# Template register map
Vendor: VendorName Co.Ltd; Series: SeriesName; File version: 1.2
CPU: CM7 r0p1, little endian, MPU, FPU, 4 interrupt priority bits
Registers are 32-bit, read-write, no defined reset value unless marked. A register's access mark holds for its fields unless they carry their own. Offsets are from the block's base; [hi:lo] are bit positions; lines under a group give offsets from that group; {n}, {i} and the like mark numbered series; 'fields as' and 'values as' point back to an identical list.

## XBAR — Crossbar
Base 0x40036000
{0x0+0x10*i} EPWMAOUTXMUX[{i}] (i=0..7) group — Grouping of EPWMAOUTx signal from MUX0 to MUX63
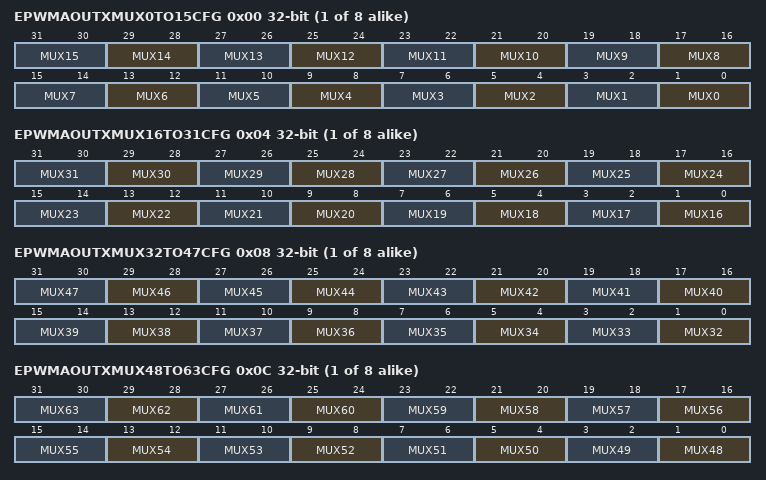
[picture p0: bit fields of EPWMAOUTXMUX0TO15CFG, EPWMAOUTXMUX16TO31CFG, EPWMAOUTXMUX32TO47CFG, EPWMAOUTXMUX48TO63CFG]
  0x00 EPWMAOUTXMUX0TO15CFG — EPWM XBAR A OUTx multiplexing config register 1
    [2n+1:2n] MUX{n} (n=0..15) — XBAR MUX{n}[1:0] bit: input signal of EPWM XBAR A OUTxMUX{n} select
  0x04 EPWMAOUTXMUX16TO31CFG — EPWM XBAR A OUTx multiplexing config register 2
    [2n-31:2n-32] MUX{n} (n=16..31) — XBAR MUX{n}[1:0] bit: input signal of EPWM XBAR A OUTxMUX{n} select
  0x08 EPWMAOUTXMUX32TO47CFG — EPWM XBAR A OUTx multiplexing config register 3
    [2n-63:2n-64] MUX{n} (n=32..47) — XBAR MUX{n}[1:0] bit: input signal of EPWM XBAR A OUTxMUX{n} select
  0x0C EPWMAOUTXMUX48TO63CFG — EPWM XBAR A OUTx multiplexing config register 4
    [2n-95:2n-96] MUX{n} (n=48..63) — XBAR MUX{n}[1:0] bit: input signal of EPWM XBAR A OUTxMUX{n} select
{0x80+8i} EPWMAOUTPUTXMUXEN[{i}] (i=0..7) group — Grouping of EPWMAOUTx enable from MUX0 to MUX63
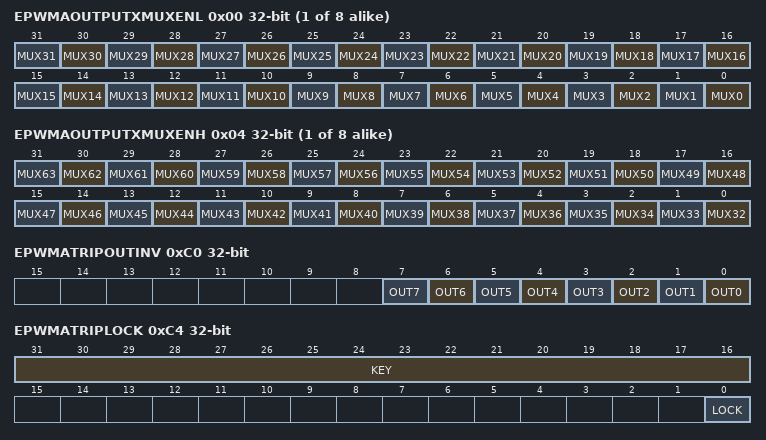
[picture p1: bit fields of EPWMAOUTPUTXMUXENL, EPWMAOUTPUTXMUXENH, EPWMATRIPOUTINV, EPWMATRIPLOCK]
  0x00 EPWMAOUTPUTXMUXENL — EPWM XBAR A OUTx enable register 1
    [n] MUX{n} (n=0..31) — XBAR MUX{n} bit: select output of MUX{n} to drive OUTPUTx of EPWM XBAR A
  0x04 EPWMAOUTPUTXMUXENH — EPWM XBAR A OUTx enable register 2
    [n-32] MUX{n} (n=32..63) — XBAR MUX{n} bit: select output of MUX{n} to drive OUTPUTx of EPWM XBAR A
0xC0 EPWMATRIPOUTINV — EPWM XBAR A output inverse register
  [n] OUT{n} (n=0..7) — XBAR OUT{n} bit: select polarity of EPWM XBAR A's TRIP{n+5}
0xC4 EPWMATRIPLOCK — EPWM XBAR A config lock register
  [31:16] KEY wo — XBAR KEY[15:0] bit: only when 0x5A5A is written can this register be written
  [0] LOCK — XBAR LOCK bit: writing lock of EPWM XBAR A register
{0x100+0x10*i} EPWMBOUTXMUX[{i}] (i=0..7) group — Grouping of EPWMBOUTx signal from MUX0 to MUX63
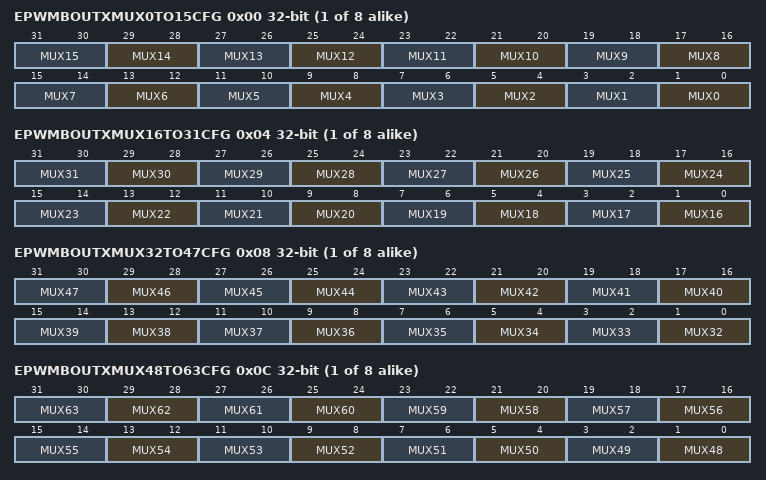
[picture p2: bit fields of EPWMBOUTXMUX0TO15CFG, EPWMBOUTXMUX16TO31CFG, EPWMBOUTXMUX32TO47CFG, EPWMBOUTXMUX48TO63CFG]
  0x00 EPWMBOUTXMUX0TO15CFG — EPWM XBAR B OUTx multiplexing config register 1
    [2n+1:2n] MUX{n} (n=0..15) — XBAR MUX{n}[1:0] bit: input signal of EPWM XBAR B OUTxMUX{n} select
  0x04 EPWMBOUTXMUX16TO31CFG — EPWM XBAR B OUTx multiplexing config register 2
    [2n-31:2n-32] MUX{n} (n=16..31) — XBAR MUX{n}[1:0] bit: input signal of EPWM XBAR B OUTxMUX{n} select
  0x08 EPWMBOUTXMUX32TO47CFG — EPWM XBAR B OUTx multiplexing config register 3
    [2n-63:2n-64] MUX{n} (n=32..47) — XBAR MUX{n}[1:0] bit: input signal of EPWM XBAR B OUTxMUX{n} select
  0x0C EPWMBOUTXMUX48TO63CFG — EPWM XBAR B OUTx multiplexing config register 4
    [2n-95:2n-96] MUX{n} (n=48..63) — XBAR MUX{n}[1:0] bit: input signal of EPWM XBAR B OUTxMUX{n} select
{0x180+8i} EPWMBOUTPUTXMUXEN[{i}] (i=0..7) group — Grouping of EPWMBOUTx enable from MUX0 to MUX63
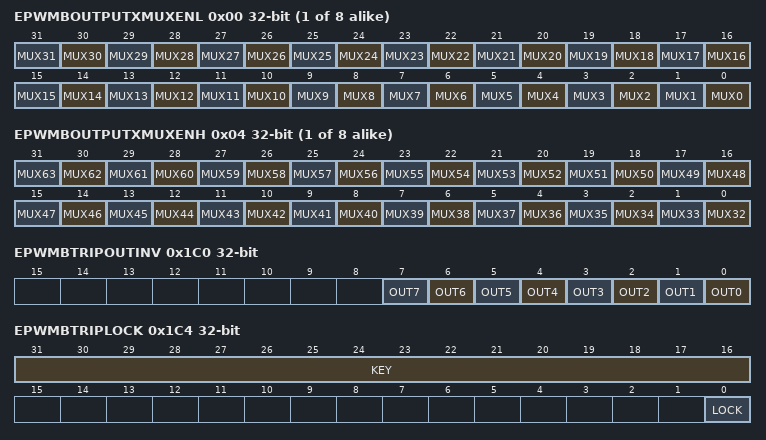
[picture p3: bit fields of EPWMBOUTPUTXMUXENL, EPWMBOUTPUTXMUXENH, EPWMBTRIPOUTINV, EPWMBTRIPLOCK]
  0x00 EPWMBOUTPUTXMUXENL — EPWM XBAR B OUTx enable register 1
    [n] MUX{n} (n=0..31) — XBAR MUX{n} bit: select output of MUX{n} to drive OUTPUTx of EPWM XBAR B
  0x04 EPWMBOUTPUTXMUXENH — EPWM XBAR B OUTx enable register 2
    [n-32] MUX{n} (n=32..63) — XBAR MUX{n} bit: select output of MUX{n} to drive OUTPUTx of EPWM XBAR B
0x1C0 EPWMBTRIPOUTINV — EPWM XBAR B output inverse register
  [n] OUT{n} (n=0..7) — XBAR OUT{n} bit: select polarity of EPWM XBAR B's TRIP{n+5}
0x1C4 EPWMBTRIPLOCK — EPWM XBAR B config lock register
  [31:16] KEY wo — XBAR KEY[15:0] bit: only when 0x5A5A is written can this register be written
  [0] LOCK — XBAR LOCK bit: writing lock of EPWM XBAR B register
{0x200+4i} INPUTXSEL[{i}] (i=0..15) — Grouping of INPUTxSEL
  [15:0] SELECT — XBAR SELECT[15:0] bit: select GPIO for INPUTx signal
0x240 INPUTSELLOCK — XBAR input selection lock register
  [15:0] INPUTSELLOCK — XBAR INPUTSELLOCK[15:0] bit: lock bit for INPUTxSELECT register
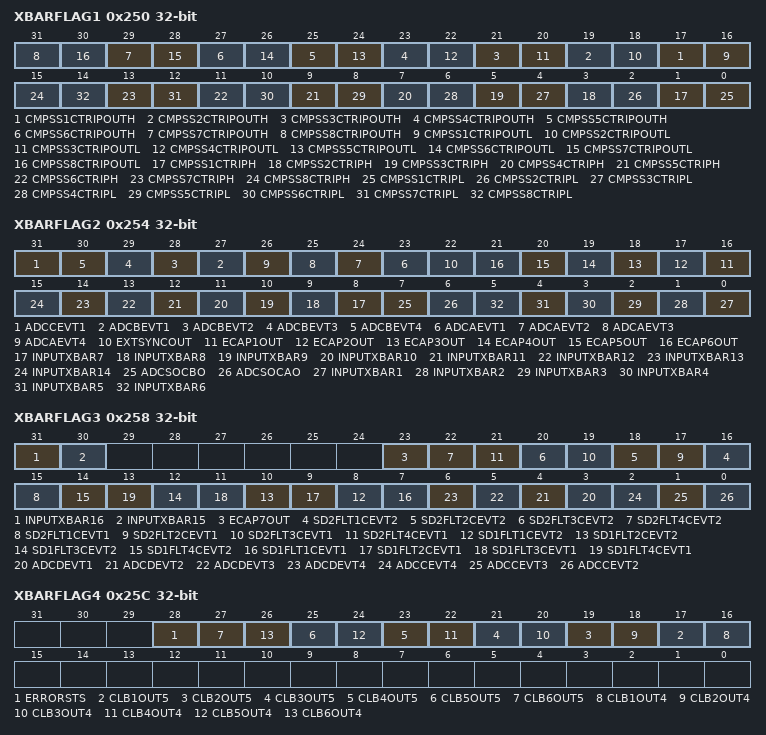
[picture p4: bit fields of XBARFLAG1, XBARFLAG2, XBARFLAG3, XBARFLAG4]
0x250 XBARFLAG1 ro — XBAR input flag register 1
  [2n+15] CMPSS{n}CTRIPOUTH (n=1..8) — XBAR CMPSS{n}CTRIPOUTH bit: whether CMPSS{n}CTRIPOUTH input was triggered
  [2n+14] CMPSS{n}CTRIPOUTL (n=1..8) — XBAR CMPSS{n}CTRIPOUTL bit: whether CMPSS{n}CTRIPOUTL input was triggered
  [2n-1] CMPSS{n}CTRIPH (n=1..8) — XBAR CMPSS{n}CTRIPH bit: whether CMPSS{n}CTRIPH input was triggered
  [2n-2] CMPSS{n}CTRIPL (n=1..8) — XBAR CMPSS{n}CTRIPL bit: whether CMPSS{n}CTRIPL input was triggered
0x254 XBARFLAG2 ro — XBAR flag register 2
  [31] ADCCEVT1 — XBAR ADCCEVT1 bit: whether ADCCEVT1 input was triggered
  [n+26] ADCBEVT{n} (n=1..4) — XBAR ADCBEVT{n} bit: whether ADCBEVT{n} input was triggered
  [n+22] ADCAEVT{n} (n=1..4) — XBAR ADCAEVT{n} bit: whether ADCAEVT{n} input was triggered
  [22] EXTSYNCOUT — XBAR EXTSYNCOUT bit: whether EXTSYNCOUT input was triggered
  [n+15] ECAP{n}OUT (n=1..6) — XBAR ECAP{n}OUT bit: whether ECAP{n}OUT input was triggered
  [n+1] INPUTXBAR{n} (n=7..14) — XBAR INPUTXBAR{n} bit: whether INPUTXBAR{n} input was triggered
  [7] ADCSOCBO — XBAR ADCSOCBO bit: whether ADCSOCBO input was triggered
  [6] ADCSOCAO — XBAR ADCSOCAO bit: whether ADCSOCAO input was triggered
  [n-1] INPUTXBAR{n} (n=1..6) — XBAR INPUTXBAR{n} bit: whether INPUTXBAR{n} input was triggered
0x258 XBARFLAG3 ro — XBAR flag register 3
  [31] INPUTXBAR16 — XBAR INPUTXBAR16 bit: whether INPUTXBAR16 input was triggered
  [30] INPUTXBAR15 — XBAR INPUTXBAR15 bit: whether INPUTXBAR15 input was triggered
  [23] ECAP7OUT — XBAR ECAP7OUT bit: whether ECAP7OUT input was triggered
  [2n+14] SD2FLT{n}CEVT2 (n=1..4) — XBAR SD2FLT{n}CEVT2 bit: whether SD2FLT{n}CEVT2 input was triggered
  [2n+13] SD2FLT{n}CEVT1 (n=1..4) — XBAR SD2FLT{n}CEVT1 bit: whether SD2FLT{n}CEVT1 input was triggered
  [2n+6] SD1FLT{n}CEVT2 (n=1..4) — XBAR SD1FLT{n}CEVT2 bit: whether SD1FLT{n}CEVT2 input was triggered
  [2n+5] SD1FLT{n}CEVT1 (n=1..4) — XBAR SD1FLT{n}CEVT1 bit: whether SD1FLT{n}CEVT1 input was triggered
  [n+2] ADCDEVT{n} (n=1..4) — XBAR ADCDEVT{n} bit: whether ADCDEVT{n} input was triggered
  [2] ADCCEVT4 — XBAR ADCCEVT4 bit: whether ADCCEVT4 input was triggered
  [1] ADCCEVT3 — XBAR ADCCEVT3 bit: whether ADCCEVT3 input was triggered
  [0] ADCCEVT2 — XBAR ADCCEVT2 bit: whether ADCCEVT2 input was triggered
0x25C XBARFLAG4 ro — XBAR flag register 4
  [28] ERRORSTS — XBAR ERRORSTS bit: whether ERRORSTS input was triggered
  [2n+15] CLB{n}OUT5 (n=1..6) — XBAR CLB{n}OUT5 bit: whether CLB{n}OUT5 input was triggered
  [2n+14] CLB{n}OUT4 (n=1..6) — XBAR CLB{n}OUT4 bit: whether CLB{n}OUT4 input was triggered
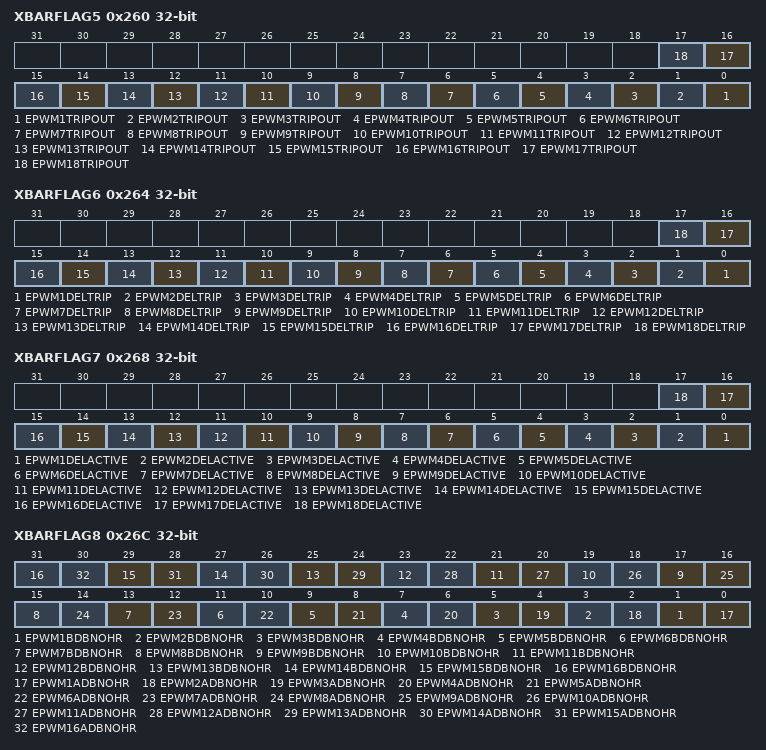
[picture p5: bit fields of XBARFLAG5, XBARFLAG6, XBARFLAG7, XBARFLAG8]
0x260 XBARFLAG5 ro — XBAR flag register 5
  [n-1] EPWM{n}TRIPOUT (n=1..18) — XBAR EPWM{n}TRIPOUT bit: whether EPWM{n}TRIPOUT input was triggered
0x264 XBARFLAG6 ro — XBAR flag register 6
  [n-1] EPWM{n}DELTRIP (n=1..18) — XBAR EPWM{n}DELTRIP bit: whether EPWM{n}DELTRIP input was triggered
0x268 XBARFLAG7 ro — XBAR flag register 7
  [n-1] EPWM{n}DELACTIVE (n=1..18) — XBAR EPWM{n}DELACTIVE bit: whether EPWM{n}DELACTIVE input was triggered
0x26C XBARFLAG8 ro — XBAR flag register 8
  [2n-1] EPWM{n}BDBNOHR (n=1..16) — XBAR EPWM{n}BDBNOHR bit: whether EPWM{n}BDBNOHR input was triggered
  [2n-2] EPWM{n}ADBNOHR (n=1..16) — XBAR EPWM{n}ADBNOHR bit: whether EPWM{n}ADBNOHR input was triggered
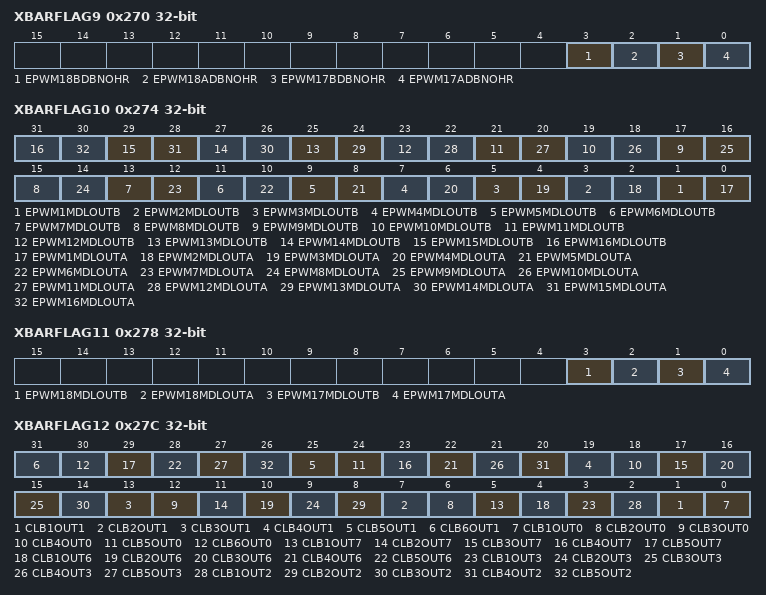
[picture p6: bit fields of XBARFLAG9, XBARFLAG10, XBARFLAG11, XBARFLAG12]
0x270 XBARFLAG9 ro — XBAR flag register 9
  [3] EPWM18BDBNOHR — XBAR EPWM18BDBNOHR bit: whether EPWM18BDBNOHR input was triggered
  [2] EPWM18ADBNOHR — XBAR EPWM18ADBNOHR bit: whether EPWM18ADBNOHR input was triggered
  [1] EPWM17BDBNOHR — XBAR EPWM17BDBNOHR bit: whether EPWM17BDBNOHR input was triggered
  [0] EPWM17ADBNOHR — XBAR EPWM17ADBNOHR bit: whether EPWM17ADBNOHR input was triggered
0x274 XBARFLAG10 ro — XBAR flag register 10
  [2n-1] EPWM{n}MDLOUTB (n=1..16) — XBAR EPWM{n}MDLOUTB bit: whether EPWM{n}MDLOUTB input was triggered
  [2n-2] EPWM{n}MDLOUTA (n=1..16) — XBAR EPWM{n}MDLOUTA bit: whether EPWM{n}MDLOUTA input was triggered
0x278 XBARFLAG11 ro — XBAR flag register 11
  [3] EPWM18MDLOUTB — XBAR EPWM18MDLOUTB bit: whether EPWM18MDLOUTB input was triggered
  [2] EPWM18MDLOUTA — XBAR EPWM18MDLOUTA bit: whether EPWM18MDLOUTA input was triggered
  [1] EPWM17MDLOUTB — XBAR EPWM17MDLOUTB bit: whether EPWM17MDLOUTB input was triggered
  [0] EPWM17MDLOUTA — XBAR EPWM17MDLOUTA bit: whether EPWM17MDLOUTA input was triggered
0x27C XBARFLAG12 ro — XBAR flag register 12
  [6n-5] CLB{n}OUT1 (n=1..6) — XBAR CLB{n}OUT1 bit: whether CLB{n}OUT1 input was triggered
  [6n-6] CLB{n}OUT0 (n=1..6) — XBAR CLB{n}OUT0 bit: whether CLB{n}OUT0 input was triggered
  [6n-1] CLB{n}OUT7 (n=1..5) — XBAR CLB{n}OUT7 bit: whether CLB{n}OUT7 input was triggered
  [6n-2] CLB{n}OUT6 (n=1..5) — XBAR CLB{n}OUT6 bit: whether CLB{n}OUT6 input was triggered
  [6n-3] CLB{n}OUT3 (n=1..5) — XBAR CLB{n}OUT3 bit: whether CLB{n}OUT3 input was triggered
  [6n-4] CLB{n}OUT2 (n=1..5) — XBAR CLB{n}OUT2 bit: whether CLB{n}OUT2 input was triggered
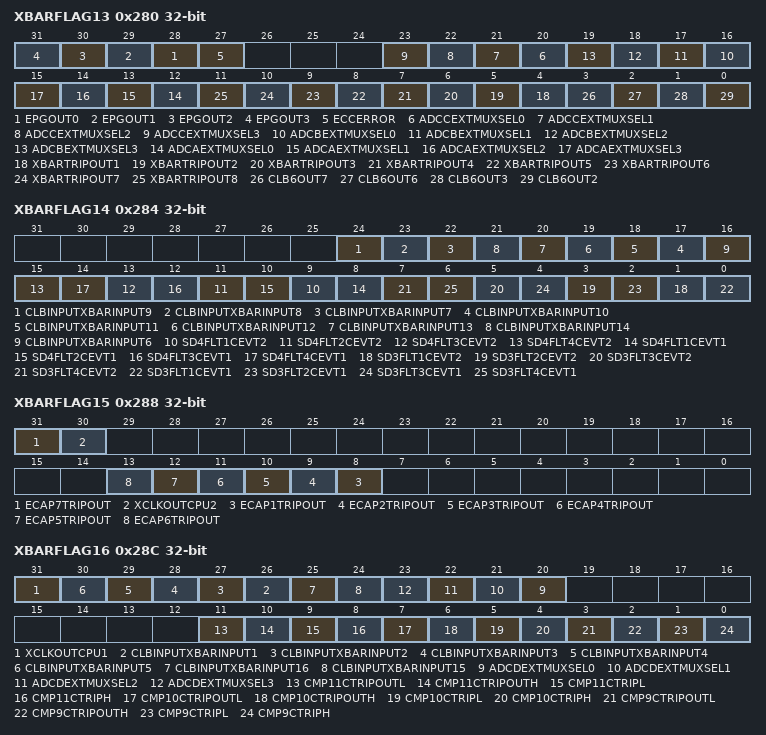
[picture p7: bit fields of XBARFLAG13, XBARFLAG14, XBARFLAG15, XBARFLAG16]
0x280 XBARFLAG13 ro — XBAR flag register 13
  [n+28] EPGOUT{n} (n=0..3) — XBAR EPGOUT{n} bit: whether EPGOUT{n} input was triggered
  [27] ECCERROR — XBAR ECCERROR bit: whether ECCERROR input was triggered
  [n+20] ADCCEXTMUXSEL{n} (n=0..3) — XBAR ADCCEXTMUXSEL{n} bit: whether ADCCEXTMUXSEL{n} input was triggered
  [n+16] ADCBEXTMUXSEL{n} (n=0..3) — XBAR ADCBEXTMUXSEL{n} bit: whether ADCBEXTMUXSEL{n} input was triggered
  [n+12] ADCAEXTMUXSEL{n} (n=0..3) — XBAR ADCAEXTMUXSEL{n} bit: whether ADCAEXTMUXSEL{n} input was triggered
  [n+3] XBARTRIPOUT{n} (n=1..8) — XBAR XBARTRIPOUT{n} bit: whether XBARTRIPOUT{n} input was triggered
  [3] CLB6OUT7 — XBAR CLB6OUT7 bit: whether CLB6OUT7 input was triggered
  [2] CLB6OUT6 — XBAR CLB6OUT6 bit: whether CLB6OUT6 input was triggered
  [1] CLB6OUT3 — XBAR CLB6OUT3 bit: whether CLB6OUT3 input was triggered
  [0] CLB6OUT2 — XBAR CLB6OUT2 bit: whether CLB6OUT2 input was triggered
0x284 XBARFLAG14 ro — XBAR flag register 14
  [24] CLBINPUTXBARINPUT9 — XBAR CLBINPUTXBARINPUT9 bit: whether CLBINPUTXBARINPUT9 input was triggered
  [23] CLBINPUTXBARINPUT8 — XBAR CLBINPUTXBARINPUT8 bit: whether CLBINPUTXBARINPUT8 input was triggered
  [22] CLBINPUTXBARINPUT7 — XBAR CLBINPUTXBARINPUT7 bit: whether CLBINPUTXBARINPUT7 input was triggered
  [n+7] CLBINPUTXBARINPUT{n} (n=10..14) — XBAR CLBINPUTXBARINPUT{n} bit: whether CLBINPUTXBARINPUT{n} input was triggered
  [16] CLBINPUTXBARINPUT6 — XBAR CLBINPUTXBARINPUT6 bit: whether CLBINPUTXBARINPUT6 input was triggered
  [2n+7] SD4FLT{n}CEVT2 (n=1..4) — XBAR SD4FLT{n}CEVT2 bit: whether SD4FLT{n}CEVT2 input was triggered
  [2n+6] SD4FLT{n}CEVT1 (n=1..4) — XBAR SD4FLT{n}CEVT1 bit: whether SD4FLT{n}CEVT1 input was triggered
  [2n-1] SD3FLT{n}CEVT2 (n=1..4) — XBAR SD3FLT{n}CEVT2 bit: whether SD3FLT{n}CEVT2 input was triggered
  [2n-2] SD3FLT{n}CEVT1 (n=1..4) — XBAR SD3FLT{n}CEVT1 bit: whether SD3FLT{n}CEVT1 input was triggered
0x288 XBARFLAG15 ro — XBAR flag register 15
  [31] ECAP7TRIPOUT — XBAR ECAP7TRIPOUT bit: whether ECAP7TRIPOUT input was triggered
  [30] XCLKOUTCPU2 — XBAR XCLKOUTCPU2 bit: whether XCLKOUTCPU2 input was triggered
  [n+7] ECAP{n}TRIPOUT (n=1..6) — XBAR ECAP{n}TRIPOUT bit: whether ECAP{n}TRIPOUT input was triggered
0x28C XBARFLAG16 ro — XBAR flag register 16
  [31] XCLKOUTCPU1 — XBAR XCLKOUTCPU1 bit: whether XCLKOUTCPU1 input was triggered
  [n+25] CLBINPUTXBARINPUT{n} (n=1..5) — XBAR CLBINPUTXBARINPUT{n} bit: whether CLBINPUTXBARINPUT{n} input was triggered
  [25] CLBINPUTXBARINPUT16 — XBAR CLBINPUTXBARINPUT16 bit: whether CLBINPUTXBARINPUT16 input was triggered
  [24] CLBINPUTXBARINPUT15 — XBAR CLBINPUTXBARINPUT15 bit: whether CLBINPUTXBARINPUT15 input was triggered
  [n+20] ADCDEXTMUXSEL{n} (n=0..3) — XBAR ADCDEXTMUXSEL{n} bit: whether ADCDEXTMUXSEL{n} input was triggered
  [11] CMP11CTRIPOUTL — XBAR CMP11CTRIPOUTL bit: whether CMP11CTRIPOUTL input was triggered
  [10] CMP11CTRIPOUTH — XBAR CMP11CTRIPOUTH bit: whether CMP11CTRIPOUTH input was triggered
  [9] CMP11CTRIPL — XBAR CMP11CTRIPL bit: whether CMP11CTRIPL input was triggered
  [8] CMP11CTRIPH — XBAR CMP11CTRIPH bit: whether CMP11CTRIPH input was triggered
  [7] CMP10CTRIPOUTL — XBAR CMP10CTRIPOUTL bit: whether CMP10CTRIPOUTL input was triggered
  [6] CMP10CTRIPOUTH — XBAR CMP10CTRIPOUTH bit: whether CMP10CTRIPOUTH input was triggered
  [5] CMP10CTRIPL — XBAR CMP10CTRIPL bit: whether CMP10CTRIPL input was triggered
  [4] CMP10CTRIPH — XBAR CMP10CTRIPH bit: whether CMP10CTRIPH input was triggered
  [3] CMP9CTRIPOUTL — XBAR CMP9CTRIPOUTL bit: whether CMP9CTRIPOUTL input was triggered
  [2] CMP9CTRIPOUTH — XBAR CMP9CTRIPOUTH bit: whether CMP9CTRIPOUTH input was triggered
  [1] CMP9CTRIPL — XBAR CMP9CTRIPL bit: whether CMP9CTRIPL input was triggered
  [0] CMP9CTRIPH — XBAR CMP9CTRIPH bit: whether CMP9CTRIPH input was triggered
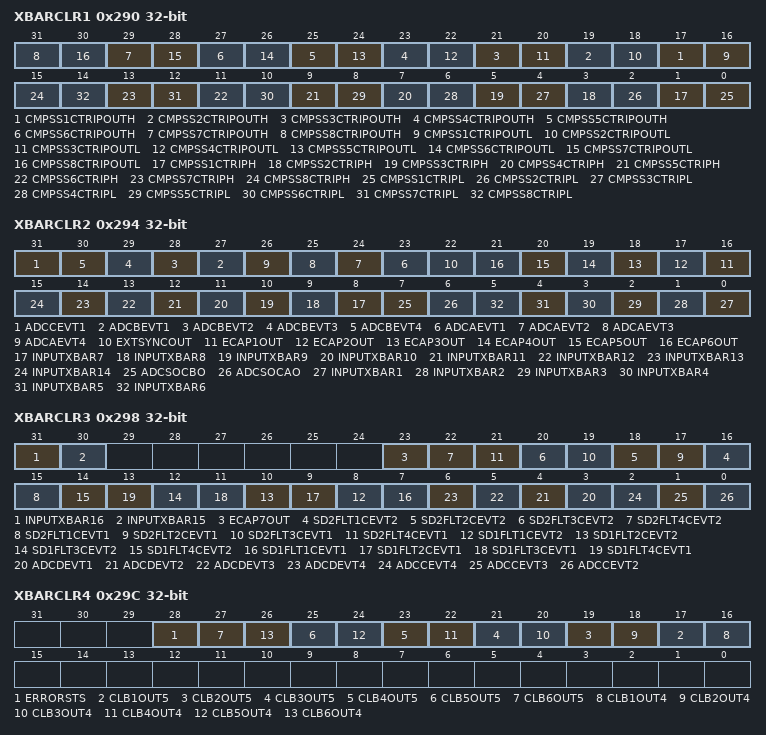
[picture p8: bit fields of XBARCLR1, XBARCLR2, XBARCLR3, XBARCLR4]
0x290 XBARCLR1 — XBAR input flag clear register 1
  [2n+15] CMPSS{n}CTRIPOUTH (n=1..8) — XBAR CMPSS{n}CTRIPOUTH bit: whether CMPSS{n}CTRIPOUTH input flag was cleared
  [2n+14] CMPSS{n}CTRIPOUTL (n=1..8) — XBAR CMPSS{n}CTRIPOUTL bit: whether CMPSS{n}CTRIPOUTL input flag was cleared
  [2n-1] CMPSS{n}CTRIPH (n=1..8) — XBAR CMPSS{n}CTRIPH bit: whether CMPSS{n}CTRIPH input flag was cleared
  [2n-2] CMPSS{n}CTRIPL (n=1..8) — XBAR CMPSS{n}CTRIPL bit: whether CMPSS{n}CTRIPL input flag was cleared
0x294 XBARCLR2 — XBAR input flag clear register 2
  [31] ADCCEVT1 — XBAR ADCCEVT1 bit: whether ADCCEVT1 input flag was cleared
  [n+26] ADCBEVT{n} (n=1..4) — XBAR ADCBEVT{n} bit: whether ADCBEVT{n} input flag was cleared
  [n+22] ADCAEVT{n} (n=1..4) — XBAR ADCAEVT{n} bit: whether ADCAEVT{n} input flag was cleared
  [22] EXTSYNCOUT — XBAR EXTSYNCOUT bit: whether EXTSYNCOUT input flag was cleared
  [n+15] ECAP{n}OUT (n=1..6) — XBAR ECAP{n}OUT bit: whether ECAP{n}OUT input flag was cleared
  [n+1] INPUTXBAR{n} (n=7..14) — XBAR INPUTXBAR{n} bit: whether INPUTXBAR{n} input flag was cleared
  [7] ADCSOCBO — XBAR ADCSOCBO bit: whether ADCSOCBO input flag was cleared
  [6] ADCSOCAO — XBAR ADCSOCAO bit: whether ADCSOCAO input flag was cleared
  [n-1] INPUTXBAR{n} (n=1..6) — XBAR INPUTXBAR{n} bit: whether INPUTXBAR{n} input flag was cleared
0x298 XBARCLR3 — XBAR input flag clear register 3
  [31] INPUTXBAR16 — XBAR INPUTXBAR16 bit: whether INPUTXBAR16 input flag was cleared
  [30] INPUTXBAR15 — XBAR INPUTXBAR15 bit: whether INPUTXBAR15 input flag was cleared
  [23] ECAP7OUT — XBAR ECAP7OUT bit: whether ECAP7OUT input flag was cleared
  [2n+14] SD2FLT{n}CEVT2 (n=1..4) — XBAR SD2FLT{n}CEVT2 bit: whether SD2FLT{n}CEVT2 input flag was cleared
  [2n+13] SD2FLT{n}CEVT1 (n=1..4) — XBAR SD2FLT{n}CEVT1 bit: whether SD2FLT{n}CEVT1 input flag was cleared
  [2n+6] SD1FLT{n}CEVT2 (n=1..4) — XBAR SD1FLT{n}CEVT2 bit: whether SD1FLT{n}CEVT2 input flag was cleared
  [2n+5] SD1FLT{n}CEVT1 (n=1..4) — XBAR SD1FLT{n}CEVT1 bit: whether SD1FLT{n}CEVT1 input flag was cleared
  [n+2] ADCDEVT{n} (n=1..4) — XBAR ADCDEVT{n} bit: whether ADCDEVT{n} input flag was cleared
  [2] ADCCEVT4 — XBAR ADCCEVT4 bit: whether ADCCEVT4 input flag was cleared
  [1] ADCCEVT3 — XBAR ADCCEVT3 bit: whether ADCCEVT3 input flag was cleared
  [0] ADCCEVT2 — XBAR ADCCEVT2 bit: whether ADCCEVT2 input flag was cleared
0x29C XBARCLR4 — XBAR input flag clear register 4
  [28] ERRORSTS — XBAR ERRORSTS bit: whether ERRORSTS input flag was cleared
  [2n+15] CLB{n}OUT5 (n=1..6) — XBAR CLB{n}OUT5 bit: whether CLB{n}OUT5 input flag was cleared
  [2n+14] CLB{n}OUT4 (n=1..6) — XBAR CLB{n}OUT4 bit: whether CLB{n}OUT4 input flag was cleared
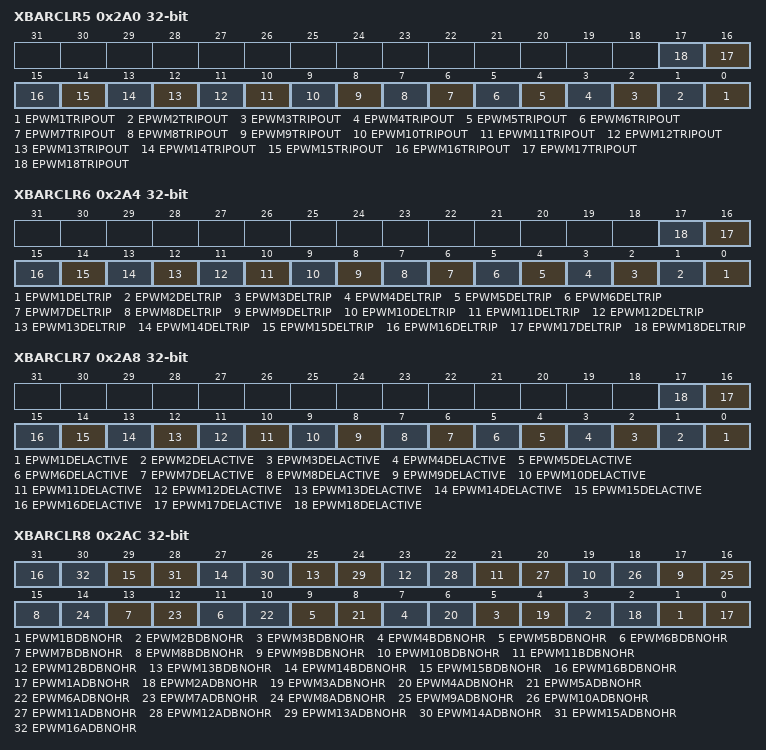
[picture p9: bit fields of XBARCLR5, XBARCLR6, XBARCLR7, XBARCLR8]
0x2A0 XBARCLR5 — XBAR input flag clear register 5
  [n-1] EPWM{n}TRIPOUT (n=1..18) — XBAR EPWM{n}TRIPOUT bit: whether EPWM{n}TRIPOUT input flag was cleared
0x2A4 XBARCLR6 — XBAR input flag clear register 6
  [n-1] EPWM{n}DELTRIP (n=1..18) — XBAR EPWM{n}DELTRIP bit: whether EPWM{n}DELTRIP input flag was cleared
0x2A8 XBARCLR7 — XBAR input flag clear register 7
  [n-1] EPWM{n}DELACTIVE (n=1..18) — XBAR EPWM{n}DELACTIVE bit: whether EPWM{n}DELACTIVE input flag was cleared
0x2AC XBARCLR8 — XBAR input flag clear register 8
  [2n-1] EPWM{n}BDBNOHR (n=1..16) — XBAR EPWM{n}BDBNOHR bit: whether EPWM{n}BDBNOHR input flag was cleared
  [2n-2] EPWM{n}ADBNOHR (n=1..16) — XBAR EPWM{n}ADBNOHR bit: whether EPWM{n}ADBNOHR input flag was cleared
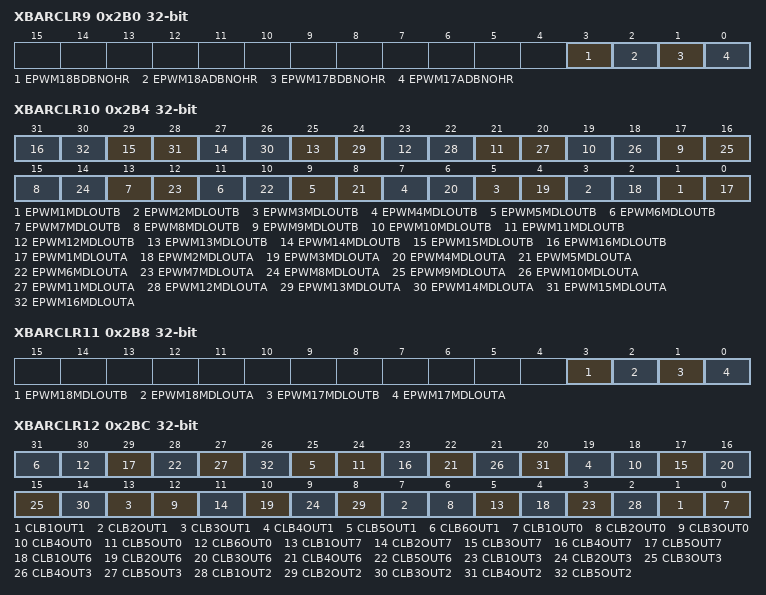
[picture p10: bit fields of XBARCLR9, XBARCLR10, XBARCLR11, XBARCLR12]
0x2B0 XBARCLR9 — XBAR input flag clear register 9
  [3] EPWM18BDBNOHR — XBAR EPWM18BDBNOHR bit: whether EPWM18BDBNOHR input flag was cleared
  [2] EPWM18ADBNOHR — XBAR EPWM18ADBNOHR bit: whether EPWM18ADBNOHR input flag was cleared
  [1] EPWM17BDBNOHR — XBAR EPWM17BDBNOHR bit: whether EPWM17BDBNOHR input flag was cleared
  [0] EPWM17ADBNOHR — XBAR EPWM17ADBNOHR bit: whether EPWM17ADBNOHR input flag was cleared
0x2B4 XBARCLR10 — XBAR input flag clear register 10
  [2n-1] EPWM{n}MDLOUTB (n=1..16) — XBAR EPWM{n}MDLOUTB bit: whether EPWM{n}MDLOUTB input flag was cleared
  [2n-2] EPWM{n}MDLOUTA (n=1..16) — XBAR EPWM{n}MDLOUTA bit: whether EPWM{n}MDLOUTA input flag was cleared
0x2B8 XBARCLR11 — XBAR input flag clear register 11
  [3] EPWM18MDLOUTB — XBAR EPWM18MDLOUTB bit: whether EPWM18MDLOUTB input flag was cleared
  [2] EPWM18MDLOUTA — XBAR EPWM18MDLOUTA bit: whether EPWM18MDLOUTA input flag was cleared
  [1] EPWM17MDLOUTB — XBAR EPWM17MDLOUTB bit: whether EPWM17MDLOUTB input flag was cleared
  [0] EPWM17MDLOUTA — XBAR EPWM17MDLOUTA bit: whether EPWM17MDLOUTA input flag was cleared
0x2BC XBARCLR12 — XBAR input flag clear register 12
  [6n-5] CLB{n}OUT1 (n=1..6) — XBAR CLB{n}OUT1 bit: whether CLB{n}OUT1 input flag was cleared
  [6n-6] CLB{n}OUT0 (n=1..6) — XBAR CLB{n}OUT0 bit: whether CLB{n}OUT0 input flag was cleared
  [6n-1] CLB{n}OUT7 (n=1..5) — XBAR CLB{n}OUT7 bit: whether CLB{n}OUT7 input flag was cleared
  [6n-2] CLB{n}OUT6 (n=1..5) — XBAR CLB{n}OUT6 bit: whether CLB{n}OUT6 input flag was cleared
  [6n-3] CLB{n}OUT3 (n=1..5) — XBAR CLB{n}OUT3 bit: whether CLB{n}OUT3 input flag was cleared
  [6n-4] CLB{n}OUT2 (n=1..5) — XBAR CLB{n}OUT2 bit: whether CLB{n}OUT2 input flag was cleared
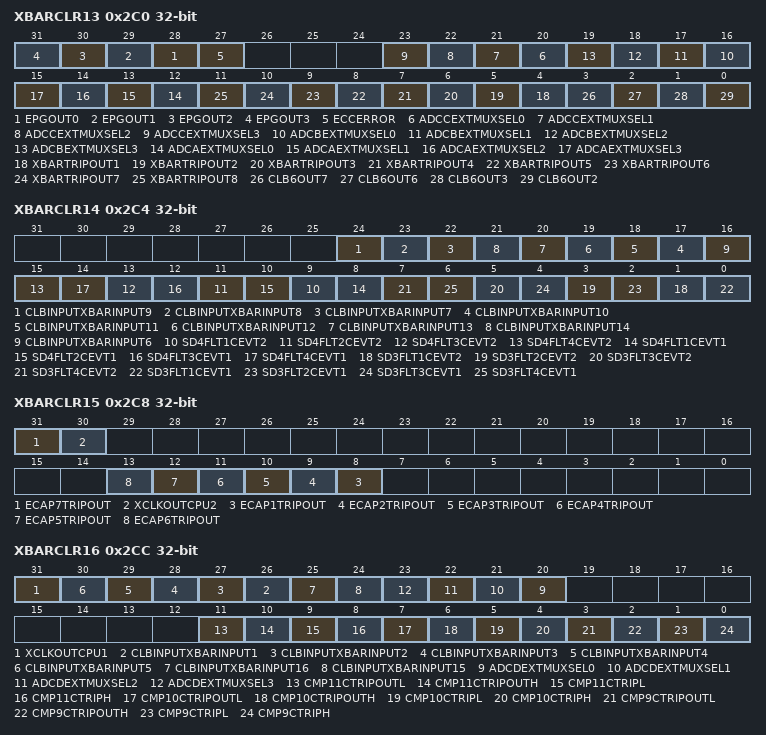
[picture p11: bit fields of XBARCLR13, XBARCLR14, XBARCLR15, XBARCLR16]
0x2C0 XBARCLR13 — XBAR input flag clear register 13
  [n+28] EPGOUT{n} (n=0..3) — XBAR EPGOUT{n} bit: whether EPGOUT{n} input flag was cleared
  [27] ECCERROR — XBAR ECCERROR bit: whether ECCERROR input flag was cleared
  [n+20] ADCCEXTMUXSEL{n} (n=0..3) — XBAR ADCCEXTMUXSEL{n} bit: whether ADCCEXTMUXSEL{n} input flag was cleared
  [n+16] ADCBEXTMUXSEL{n} (n=0..3) — XBAR ADCBEXTMUXSEL{n} bit: whether ADCBEXTMUXSEL{n} input flag was cleared
  [n+12] ADCAEXTMUXSEL{n} (n=0..3) — XBAR ADCAEXTMUXSEL{n} bit: whether ADCAEXTMUXSEL{n} input flag was cleared
  [n+3] XBARTRIPOUT{n} (n=1..8) — XBAR XBARTRIPOUT{n} bit: whether XBARTRIPOUT{n} input flag was cleared
  [3] CLB6OUT7 — XBAR CLB6OUT7 bit: whether CLB6OUT7 input flag was cleared
  [2] CLB6OUT6 — XBAR CLB6OUT6 bit: whether CLB6OUT6 input flag was cleared
  [1] CLB6OUT3 — XBAR CLB6OUT3 bit: whether CLB6OUT3 input flag was cleared
  [0] CLB6OUT2 — XBAR CLB6OUT2 bit: whether CLB6OUT2 input flag was cleared
0x2C4 XBARCLR14 — XBAR input flag clear register 14
  [24] CLBINPUTXBARINPUT9 — XBAR CLBINPUTXBARINPUT9 bit: whether CLBINPUTXBARINPUT9 input flag was cleared
  [23] CLBINPUTXBARINPUT8 — XBAR CLBINPUTXBARINPUT8 bit: whether CLBINPUTXBARINPUT8 input flag was cleared
  [22] CLBINPUTXBARINPUT7 — XBAR CLBINPUTXBARINPUT7 bit: whether CLBINPUTXBARINPUT7 input flag was cleared
  [n+7] CLBINPUTXBARINPUT{n} (n=10..14) — XBAR CLBINPUTXBARINPUT{n} bit: whether CLBINPUTXBARINPUT{n} input flag was cleared
  [16] CLBINPUTXBARINPUT6 — XBAR CLBINPUTXBARINPUT6 bit: whether CLBINPUTXBARINPUT6 input flag was cleared
  [2n+7] SD4FLT{n}CEVT2 (n=1..4) — XBAR SD4FLT{n}CEVT2 bit: whether SD4FLT{n}CEVT2 input flag was cleared
  [2n+6] SD4FLT{n}CEVT1 (n=1..4) — XBAR SD4FLT{n}CEVT1 bit: whether SD4FLT{n}CEVT1 input flag was cleared
  [2n-1] SD3FLT{n}CEVT2 (n=1..4) — XBAR SD3FLT{n}CEVT2 bit: whether SD3FLT{n}CEVT2 input flag was cleared
  [2n-2] SD3FLT{n}CEVT1 (n=1..4) — XBAR SD3FLT{n}CEVT1 bit: whether SD3FLT{n}CEVT1 input flag was cleared
0x2C8 XBARCLR15 — XBAR input flag clear register 15
  [31] ECAP7TRIPOUT — XBAR ECAP7TRIPOUT bit: whether ECAP7TRIPOUT input flag was cleared
  [30] XCLKOUTCPU2 — XBAR XCLKOUTCPU2 bit: whether XCLKOUTCPU2 input flag was cleared
  [n+7] ECAP{n}TRIPOUT (n=1..6) — XBAR ECAP{n}TRIPOUT bit: whether ECAP{n}TRIPOUT input flag was cleared
0x2CC XBARCLR16 — XBAR input flag clear register 16
  [31] XCLKOUTCPU1 — XBAR XCLKOUTCPU1 bit: whether XCLKOUTCPU1 input flag was cleared
  [n+25] CLBINPUTXBARINPUT{n} (n=1..5) — XBAR CLBINPUTXBARINPUT{n} bit: whether CLBINPUTXBARINPUT{n} input flag was cleared
  [25] CLBINPUTXBARINPUT16 — XBAR CLBINPUTXBARINPUT16 bit: whether CLBINPUTXBARINPUT16 input flag was cleared
  [24] CLBINPUTXBARINPUT15 — XBAR CLBINPUTXBARINPUT15 bit: whether CLBINPUTXBARINPUT15 input flag was cleared
  [n+20] ADCDEXTMUXSEL{n} (n=0..3) — XBAR ADCDEXTMUXSEL{n} bit: whether ADCDEXTMUXSEL{n} input flag was cleared
  [11] CMP11CTRIPOUTL — XBAR CMP11CTRIPOUTL bit: whether CMP11CTRIPOUTL input flag was cleared
  [10] CMP11CTRIPOUTH — XBAR CMP11CTRIPOUTH bit: whether CMP11CTRIPOUTH input flag was cleared
  [9] CMP11CTRIPL — XBAR CMP11CTRIPL bit: whether CMP11CTRIPL input flag was cleared
  [8] CMP11CTRIPH — XBAR CMP11CTRIPH bit: whether CMP11CTRIPH input flag was cleared
  [7] CMP10CTRIPOUTL — XBAR CMP10CTRIPOUTL bit: whether CMP10CTRIPOUTL input flag was cleared
  [6] CMP10CTRIPOUTH — XBAR CMP10CTRIPOUTH bit: whether CMP10CTRIPOUTH input flag was cleared
  [5] CMP10CTRIPL — XBAR CMP10CTRIPL bit: whether CMP10CTRIPL input flag was cleared
  [4] CMP10CTRIPH — XBAR CMP10CTRIPH bit: whether CMP10CTRIPH input flag was cleared
  [3] CMP9CTRIPOUTL — XBAR CMP9CTRIPOUTL bit: whether CMP9CTRIPOUTL input flag was cleared
  [2] CMP9CTRIPOUTH — XBAR CMP9CTRIPOUTH bit: whether CMP9CTRIPOUTH input flag was cleared
  [1] CMP9CTRIPL — XBAR CMP9CTRIPL bit: whether CMP9CTRIPL input flag was cleared
  [0] CMP9CTRIPH — XBAR CMP9CTRIPH bit: whether CMP9CTRIPH input flag was cleared
{0x2D0+4i} CLBINPUTXSEL[{i}] (i=0..15) — Grouping of CLBINPUTxSEL
  [15:0] SELECT — XBAR SELECT[15:0] bit: select which GPIO as input signal of INPUTx
0x310 CLBINSELLOCK — XBAR CLB input selection lock register
  [15:0] CLBINSELLOCK — XBAR CLBINSELLOCK[15:0] bit: CLB input selection lock
{0x400+4i} MDLXSEL[{i}] (i=0..15) — Grouping of MDLxSEL
  [7:0] SELECT — XBAR SELECT[7:0] bit: input signal of MDLxSEL select
0x440 MDLSELLOCK — XBAR MDL input selection control register
  [15:0] MDLSELLOCK — XBAR MDLSELLOCK[15:0] bit: MDL input selection lock
{0x450+4i} ICLXSEL[{i}] (i=0..15) — Grouping of MDLxSEL
  [7:0] SELECT — XBAR SELECT[7:0] bit: input signal of ICLxSEL select
0x490 ICLSELLOCK — XBAR ICL input selection control register
  [15:0] ICLSELLOCK — XBAR ICLSELLOCK[15:0] bit: ICL input selection lock
{0x4A0+8i} AUXSIGXMUX[{i}] (i=0..7) group — Grouping of AUXSIGx signal from MUX0 to MUX31
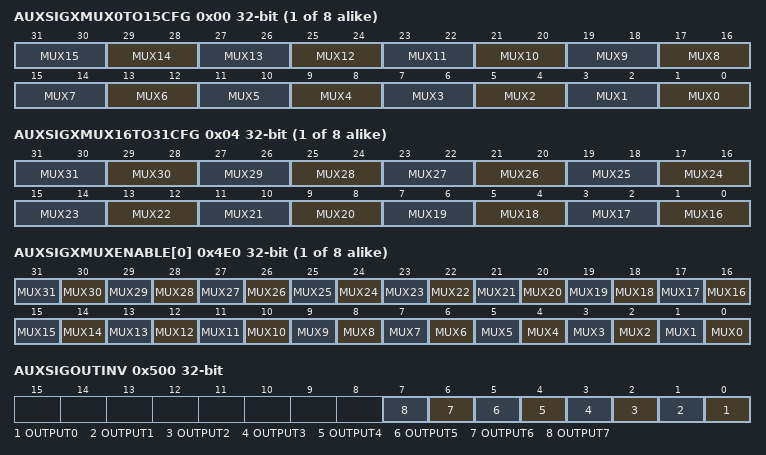
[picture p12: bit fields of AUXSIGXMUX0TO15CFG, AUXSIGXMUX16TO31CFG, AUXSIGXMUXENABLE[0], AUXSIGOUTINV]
  0x00 AUXSIGXMUX0TO15CFG — CLB XBAR AUXSIGx multiplexing config register 1
    [2n+1:2n] MUX{n} (n=0..15) — XBAR MUX{n}[1:0] bit: input signal of CLB XBAR AUXSIGx's MUX{n} select
  0x04 AUXSIGXMUX16TO31CFG — CLB XBAR AUXSIGx multiplexing config register 2
    [2n-31:2n-32] MUX{n} (n=16..31) — XBAR MUX{n}[1:0] bit: input signal of CLB XBAR AUXSIGx's MUX{n} select
{0x4E0+4i} AUXSIGXMUXENABLE[{i}] (i=0..7) — Grouping of AUXSIGx enable from MUX0 to MUX31
  [n] MUX{n} (n=0..31) — XBAR MUX{n} bit: select output of MUX{n} to drive AUXSIGx of CLB XBAR
0x500 AUXSIGOUTINV — CLB XBAR output inverse register
  [n] OUTPUT{n} (n=0..7) — XBAR OUTPUT{n} bit: select polarity of CLB XBAR's AUXSIG{n+1}
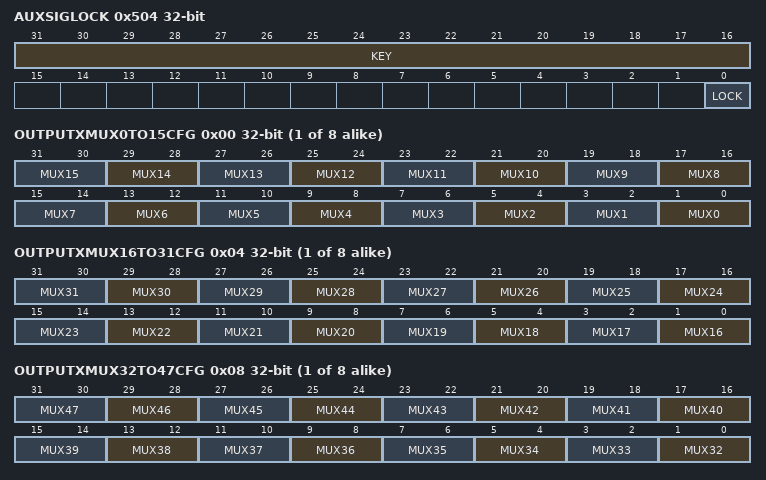
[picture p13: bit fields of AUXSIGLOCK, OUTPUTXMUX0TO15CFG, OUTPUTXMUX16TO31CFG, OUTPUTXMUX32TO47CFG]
0x504 AUXSIGLOCK — CLB XBAR config lock register
  [31:16] KEY wo — XBAR KEY[15:0] bit: only when 0x5A5A is written can this register be written
  [0] LOCK — XBAR LOCK bit: writing lock of CLB XBAR register
{0x600+0x10*i} OUTPUTXMUX[{i}] (i=0..7) group — Grouping of Output signal from MUX0 to MUX63
  0x00 OUTPUTXMUX0TO15CFG — Outputx XBAR multiplexing config register 1
    [2n+1:2n] MUX{n} (n=0..15) — XBAR MUX{n}[1:0] bit: input signal of Output XBAR OUTPUTx's MUX{n} select
  0x04 OUTPUTXMUX16TO31CFG — Outputx XBAR multiplexing config register 2
    [2n-31:2n-32] MUX{n} (n=16..31) — XBAR MUX{n}[1:0] bit: input signal of Output XBAR OUTPUTx's MUX{n} select
  0x08 OUTPUTXMUX32TO47CFG — Outputx XBAR multiplexing config register 3
    [2n-63:2n-64] MUX{n} (n=32..47) — XBAR MUX{n}[1:0] bit: input signal of Output XBAR OUTPUTx's MUX{n} select
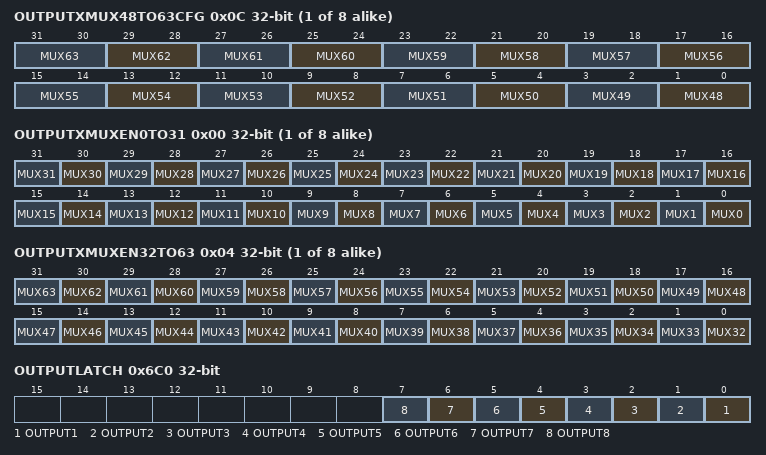
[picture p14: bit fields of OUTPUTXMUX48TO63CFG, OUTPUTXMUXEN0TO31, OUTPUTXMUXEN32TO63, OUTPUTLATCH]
  0x0C OUTPUTXMUX48TO63CFG — Outputx XBAR multiplexing config register 4
    [2n-95:2n-96] MUX{n} (n=48..63) — XBAR MUX{n}[1:0] bit: input signal of Output XBAR OUTPUTx's MUX{n} select
{0x680+8i} OUTPUTXMUXEN[{i}] (i=0..7) group — Grouping of Output signal from MUX0 to MUX63
  0x00 OUTPUTXMUXEN0TO31 — Outputx XBAR multiplexing enable register 1
    [n] MUX{n} (n=0..31) — XBAR MUX{n} bit: select output of MUX{n} to drive OUTPUTx of Output XBAR
  0x04 OUTPUTXMUXEN32TO63 — Outputx XBAR multiplexing enable register 2
    [n-32] MUX{n} (n=32..63) — XBAR MUX{n} bit: select output of MUX{n} to drive OUTPUTx of Output XBAR
0x6C0 OUTPUTLATCH ro — Output XBAR output lock register
  [n-1] OUTPUT{n} (n=1..8) — XBAR OUTPUT{n} bit: output flag of OUTPUT{n}
0x6C4 OUTPUTLATCHCLR — Output XBAR output lock clear register
  [n-1] OUTPUT{n} (n=1..8) — XBAR OUTPUT{n} bit: output flag clear of OUTPUT{n}
0x6C8 OUTPUTLATCHFRC — Output XBAR output lock set register
  [n-1] OUTPUT{n} (n=1..8) — XBAR OUTPUT{n} bit: output lock set of OUTPUT{n}
0x6CC OUTPUTLATCHENABLE — Output XBAR output lock enable register
  [n-1] OUTPUT{n} (n=1..8) — XBAR OUTPUT{n} bit: output lock enable of OUTPUT{n}
0x6D0 OUTPUTINV — Output XBAR output inverse register
  [n-1] OUTPUT{n} (n=1..8) — XBAR OUTPUT{n} bit: select polarity of OUTPUT{n}
0x6D4 OUTPUTLOCK — Output X-BAR config lock register
  [31:16] KEY wo — XBAR KEY[15:0] bit: only when 0x5A5A is written can this register be written
  [0] LOCK — XBAR LOCK bit: writing lock of Output XBAR register
{0x700+8i} CLBOUTPUTXMUX[{i}] (i=0..7) group — Grouping of CLB OUTPUTx from MUX0 to MUX31
  0x00 CLBOUTPUTXMUXL — CLB OUTPUTx XBAR multiplexing config register 1
    [2n+1:2n] MUX{n} (n=0..15) — XBAR MUX{n}[1:0] bit: input signal of CLB Output XBAR OUTPUTx's MUX{n} select
  0x04 CLBOUTPUTXMUXH — CLB OUTPUTx XBAR multiplexing config register 2
    [2n-31:2n-32] MUX{n} (n=16..31) — XBAR MUX{n}[1:0] bit: input signal of CLB Output XBAR OUTPUTx's MUX{n} select
{0x740+4i} CLBOUTPUTXMUXEN[{i}] (i=0..7) — Grouping of CLB OUTPUTx enable from MUX0 to MUX31
  [n] MUX{n} (n=0..31) — XBAR MUX{n} bit: select output of MUX{n} to drive OUTPUTx of CLB Output XBAR
0x760 CLBOUTPUTLATCH ro — CLB Output XBAR output lock register
  fields as OUTPUTLATCH
0x764 CLBOUTPUTLATCHCLR — CLB Output XBAR output lock clear register
  fields as OUTPUTLATCHCLR
0x768 CLBOUTPUTLATCHFRC — CLB Output XBAR output lock set register
  fields as OUTPUTLATCHFRC
0x76C CLBOUTPUTLATCHENABLE — CLB Output XBAR output lock enable register
  fields as OUTPUTLATCHENABLE
0x770 CLBOUTPUTINV — CLB Output XBAR output inverse register
  fields as OUTPUTINV
0x774 CLBOUTPUTLOCK — CLB Output XBAR config lock register
  [31:16] KEY wo — XBAR KEY[15:0] bit: only when 0x5A5A is written can this register be written
  [0] LOCK — XBAR LOCK bit: writing lock of CLB Output XBAR register
